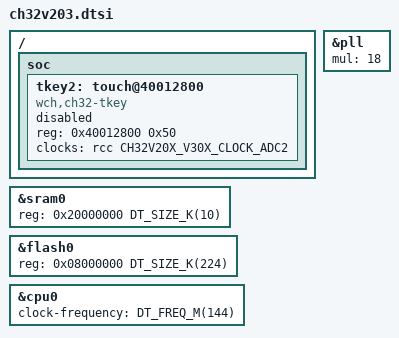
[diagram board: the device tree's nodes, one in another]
/*
 * Copyright (c) 2025 MASSDRIVER EI (massdriver.space)
 *
 * SPDX-License-Identifier: Apache-2.0
 */

#include <wch/qingke-v4b.dtsi>
#include <wch/common/ch32v20x_30x_common.dtsi>

/ {
	soc {
		tkey2: touch@40012800 {
			compatible = "wch,ch32-tkey";
			reg = <0x40012800 0x50>;
			clocks = <&rcc CH32V20X_V30X_CLOCK_ADC2>;
			status = "disabled";
		};
	};
};

&pll {
	mul = <18>;
};

&sram0 {
	reg = <0x20000000 DT_SIZE_K(10)>;
};

&flash0 {
	reg = <0x08000000 DT_SIZE_K(224)>;
	ranges = <0x0 0x08000000 DT_SIZE_K(224)>;
};

&cpu0 {
	clock-frequency = <DT_FREQ_M(144)>;
};
